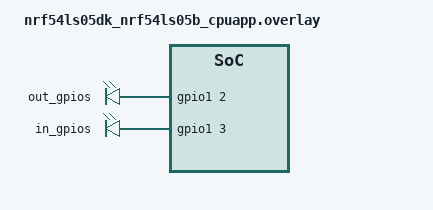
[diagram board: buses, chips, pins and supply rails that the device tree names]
/*
 * Copyright (c) 2025 Nordic Semiconductor ASA
 *
 * SPDX-License-Identifier: LicenseRef-Nordic-5-Clause
 */

/ {
	/* Test requirements:
	 * out-gpios[0] wire connected with in-gpios[0],
	 * out-gpios[1] wire connected with in-gpios[1],
	 * etc.
	 * Output-input GPIO pair must have identical active level flag.
	 */
	test_gpios {
		compatible = "gpio-leds";
		out_gpios: out_gpios {
			gpios = <&gpio1 2 GPIO_ACTIVE_HIGH>,
				<&gpio1 8 GPIO_ACTIVE_HIGH>,  <&gpio1 10 GPIO_ACTIVE_HIGH>,
				<&gpio1 14 GPIO_ACTIVE_HIGH>, <&gpio1 17 GPIO_ACTIVE_HIGH>,
				<&gpio1 19 GPIO_ACTIVE_HIGH>, <&gpio1 21 GPIO_ACTIVE_HIGH>,
				<&gpio1 23 GPIO_ACTIVE_HIGH>, <&gpio1 25 GPIO_ACTIVE_HIGH>;
		};

		in_gpios: in_gpios {
			gpios = <&gpio1 3 GPIO_ACTIVE_HIGH>,
				<&gpio1 9 GPIO_ACTIVE_HIGH>,  <&gpio1 11 GPIO_ACTIVE_HIGH>,
				<&gpio1 15 GPIO_ACTIVE_HIGH>, <&gpio1 18 GPIO_ACTIVE_HIGH>,
				<&gpio1 20 GPIO_ACTIVE_HIGH>, <&gpio1 22 GPIO_ACTIVE_HIGH>,
				<&gpio1 24 GPIO_ACTIVE_HIGH>, <&gpio1 26 GPIO_ACTIVE_HIGH>;
		};
	};
};

&gpiote20 {
	status = "okay";
};

&gpio1 {
	status = "okay";
};
